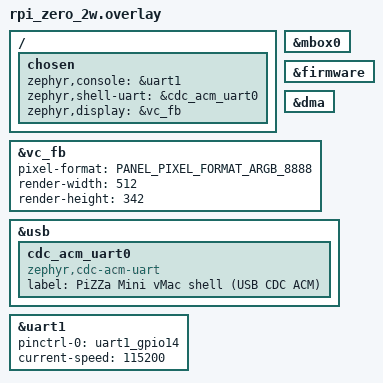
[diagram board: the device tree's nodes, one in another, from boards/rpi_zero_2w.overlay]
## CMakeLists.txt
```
# SPDX-License-Identifier: Apache-2.0
#
# PiZZa -- Mini vMac (Macintosh Plus) via the shared minimal SDL2 shim
# (apps/lib/sdl2shim). Third consumer after Doom + SDLPoP.
#
# Links the upstream Mini vMac 68K emulator core + its generated SDL2
# OS-glue (OSGLUSDL.c) against the shim. The tree at ~/github/minivmac is
# UNTOUCHED: src/ is pristine upstream, and the Mac-Plus/SDL2 variation is
# the generated cfg/ headers (setup_t -m Plus -api sd2). See the port memory.
#
# Mini vMac is GPL-2.0; this binary is GPL-2.0 by virtue of linking it. The
# shim + port glue are Apache-2.0, same model as the Doom + SDLPoP ports.

cmake_minimum_required(VERSION 3.20.0)

find_package(Zephyr REQUIRED HINTS $ENV{ZEPHYR_BASE})
project(pizza-minivmac C ASM)

# sample_usbd helper for the USB CDC ACM shell (rpi_zero_2w), same as the
# Doom / SDLPoP / wipeout ports.
if(CONFIG_USB_DEVICE_STACK_NEXT)
  include(${ZEPHYR_BASE}/samples/subsys/usb/common/common.cmake)
endif()

# ── Mini vMac tree (untouched upstream + generated cfg/) ─────────────
if(NOT DEFINED MINIVMAC_SRC_DIR)
  set(MINIVMAC_SRC_DIR "$ENV{HOME}/github/minivmac")
endif()
if(NOT EXISTS "${MINIVMAC_SRC_DIR}/src/OSGLUSDL.c")
  message(FATAL_ERROR
    "Mini vMac sources not found at ${MINIVMAC_SRC_DIR}. Clone "
    "https://github.com/minivmac/minivmac and keep it at ~/github/minivmac "
    "or pass -DMINIVMAC_SRC_DIR=<path>.")
endif()
if(NOT EXISTS "${MINIVMAC_SRC_DIR}/cfg/CNFUIOSG.h")
  message(FATAL_ERROR
    "Mini vMac Mac-Plus/SDL2 variation not generated in ${MINIVMAC_SRC_DIR}. Run:\n"
    "  cd ${MINIVMAC_SRC_DIR} && gcc -o setup_t setup/tool.c && \\\n"
    "  ./setup_t -e bgc -t larm -cpu a64 -m Plus -api sd2 -sound 1 > setup.sh && bash setup.sh")
endif()

# The generated Makefile's TU list for -m Plus -api sd2: the 68K core +
# device models + the SDL2 OS-glue. Untouched upstream.
set(MINIVMAC_SRC
  ${MINIVMAC_SRC_DIR}/src/OSGLUSDL.c
  ${MINIVMAC_SRC_DIR}/src/GLOBGLUE.c
  ${MINIVMAC_SRC_DIR}/src/M68KITAB.c
  ${MINIVMAC_SRC_DIR}/src/MINEM68K.c
  ${MINIVMAC_SRC_DIR}/src/VIAEMDEV.c
  ${MINIVMAC_SRC_DIR}/src/IWMEMDEV.c
  ${MINIVMAC_SRC_DIR}/src/SCCEMDEV.c
  ${MINIVMAC_SRC_DIR}/src/RTCEMDEV.c
  ${MINIVMAC_SRC_DIR}/src/ROMEMDEV.c
  ${MINIVMAC_SRC_DIR}/src/SCSIEMDV.c
  ${MINIVMAC_SRC_DIR}/src/SONYEMDV.c
  ${MINIVMAC_SRC_DIR}/src/SCRNEMDV.c
  ${MINIVMAC_SRC_DIR}/src/MOUSEMDV.c
  ${MINIVMAC_SRC_DIR}/src/KBRDEMDV.c
  ${MINIVMAC_SRC_DIR}/src/SNDEMDEV.c
  ${MINIVMAC_SRC_DIR}/src/PROGMAIN.c
)

# ── shim ─────────────────────────────────────────────────────────────
include(${CMAKE_CURRENT_SOURCE_DIR}/../lib/sdl2shim/sdl2shim.cmake)

set(MINIVMAC_SHIM_SRC
  src/shim_main.c
  src/minivmac_video.c
  src/minivmac_assets.c
  src/minivmac_pack.S
)

if(CONFIG_MINIVMAC_PRESENT_DISPLAY)
  list(APPEND MINIVMAC_SHIM_SRC src/minivmac_present_display.c)
elseif(CONFIG_MINIVMAC_PRESENT_SEMIHOST)
  list(APPEND MINIVMAC_SHIM_SRC src/minivmac_present_semihost.c)
else()
  list(APPEND MINIVMAC_SHIM_SRC src/minivmac_present_none.c)
endif()

# Audio backend (lib-owned choice): qemu uses "none" (Mac boots silent);
# rpi_zero_2w uses the HDMI/MAI backend later (Phase 7).
if(CONFIG_SDL2SHIM_AUDIO_HDMI)
  list(APPEND MINIVMAC_SHIM_SRC ${SDL2SHIM_AUDIO_HDMI_SOURCES})
else()
  list(APPEND MINIVMAC_SHIM_SRC ${SDL2SHIM_AUDIO_NONE})
endif()

# USB device bring-up + the `minivmac` shell = interactive input on
# hardware (key + mouse), wired at Phase 4/5.
if(CONFIG_USB_DEVICE_STACK_NEXT)
  list(APPEND MINIVMAC_SHIM_SRC ${SDL2SHIM_USB})
endif()

# The `minivmac` shell (key + mouse/click) = interactive input on hardware.
if(CONFIG_SHELL)
  list(APPEND MINIVMAC_SHIM_SRC src/minivmac_shell.c)
endif()

# Scripted synthetic input drives the Finder for the qemu sim gate.
if(CONFIG_MINIVMAC_SCRIPTED_INPUT)
  list(APPEND MINIVMAC_SHIM_SRC src/minivmac_scripted.c)
endif()

# Persistent disk backing on a mounted FATFS volume (SD card / RAM-FAT).
if(CONFIG_MINIVMAC_DISK_FS)
  list(APPEND MINIVMAC_SHIM_SRC src/minivmac_storage.c)
endif()

# BT HID input (keyboard + mouse) via apps/lib/btinput -- rpi_zero_2w only
# (boards/rpi_zero_2w.conf sets CONFIG_BTINPUT; qemu has no radio).
if(CONFIG_BTINPUT)
  include(${CMAKE_CURRENT_SOURCE_DIR}/../lib/btinput/btinput.cmake)
  # The BT patchram (.hcd) is a gitignored vendor blob (PROVENANCE.md).
  # Fail LOUDLY if missing: an empty-patchram image wedges the controller
  # at runtime (Download_Minidriver with nothing to launch).
  if(NOT CONFIG_AIROC_CUSTOM_FIRMWARE_HCD_BLOB)
    message(FATAL_ERROR
      "minivmac+BTINPUT: CONFIG_AIROC_CUSTOM_FIRMWARE_HCD_BLOB is unset")
  endif()
  set(_bt_blob "${CONFIG_AIROC_CUSTOM_FIRMWARE_HCD_BLOB}")
  if(NOT IS_ABSOLUTE "${_bt_blob}")
    set(_bt_blob "${CMAKE_CURRENT_SOURCE_DIR}/${_bt_blob}")
  endif()
  if(NOT EXISTS "${_bt_blob}")
    message(FATAL_ERROR
      "minivmac+BTINPUT: BT patchram not found:\n  ${_bt_blob}\n"
      "It is gitignored (vendor blob) -- fetch it per "
      "apps/lib/btinput/firmware/PROVENANCE.md before building.")
  endif()
  list(APPEND MINIVMAC_SHIM_SRC ${BTINPUT_SOURCES} src/minivmac_btinput.c)
endif()

# ── ROM bake (§5): raw .incbin into rodata ──────────────────────────
if(NOT DEFINED MINIVMAC_ROM)
  set(MINIVMAC_ROM "${MINIVMAC_SRC_DIR}/extras/roms/vMac.ROM")
endif()
if(NOT EXISTS "${MINIVMAC_ROM}")
  message(FATAL_ERROR "Mac Plus ROM not found: ${MINIVMAC_ROM}. Pass -DMINIVMAC_ROM=<path/to/vMac.ROM>.")
endif()
set(MINIVMAC_ROM_BIN ${CMAKE_BINARY_DIR}/minivmac_rom.bin)
add_custom_command(
  OUTPUT ${MINIVMAC_ROM_BIN}
  COMMAND ${CMAKE_COMMAND} -E copy ${MINIVMAC_ROM} ${MINIVMAC_ROM_BIN}
  DEPENDS ${MINIVMAC_ROM}
  COMMENT "Baking Mac Plus ROM ${MINIVMAC_ROM} into rodata"
)
add_custom_target(minivmac_rom_bake DEPENDS ${MINIVMAC_ROM_BIN})
add_dependencies(app minivmac_rom_bake)

# ── Boot disk bake (Phase 3): a bootable System 6.0.8 floppy into rodata,
# served through a writable RAM overlay (minivmac_assets.c). Default is the
# Startup floppy shipped in the pinned tree; the 100 MB HD image cannot be
# RAM-backed (SD/FAT persistence is a later phase).
if(NOT DEFINED MINIVMAC_DISK)
  set(MINIVMAC_DISK "${MINIVMAC_SRC_DIR}/extras/disks/608/Z-690-5830-B (Startup).img")
endif()
if(NOT EXISTS "${MINIVMAC_DISK}")
  message(FATAL_ERROR "Boot disk not found: ${MINIVMAC_DISK}. Pass -DMINIVMAC_DISK=<path/to/bootable.dsk>.")
endif()
set(MINIVMAC_DISK_BIN ${CMAKE_BINARY_DIR}/minivmac_disk.dsk)
add_custom_command(
  OUTPUT ${MINIVMAC_DISK_BIN}
  COMMAND ${CMAKE_COMMAND} -E copy "${MINIVMAC_DISK}" ${MINIVMAC_DISK_BIN}
  DEPENDS "${MINIVMAC_DISK}"
  COMMENT "Baking boot disk into rodata"
  VERBATIM
)
add_custom_target(minivmac_disk_bake DEPENDS ${MINIVMAC_DISK_BIN})
add_dependencies(app minivmac_disk_bake)

set_source_files_properties(src/minivmac_pack.S PROPERTIES
  OBJECT_DEPENDS "${MINIVMAC_ROM_BIN};${MINIVMAC_DISK_BIN}"
  COMPILE_OPTIONS "-I${CMAKE_BINARY_DIR};-Wa,-I${CMAKE_BINARY_DIR}"
)

# ── target ───────────────────────────────────────────────────────────
target_sources(app PRIVATE
  ${MINIVMAC_SRC}
  ${MINIVMAC_SHIM_SRC}
  ${SDL2SHIM_CORE_SOURCES}
)

# include order: shim SDL2 headers first so <SDL2/SDL.h> (pulled by
# cfg/CNFUIOSG.h) resolves to the shim, then the Mini vMac variation cfg/
# and the pristine upstream src/.
target_include_directories(app PRIVATE
  ${SDL2SHIM_INCLUDE_DIRS}
  ${CMAKE_CURRENT_SOURCE_DIR}/src
  ${MINIVMAC_SRC_DIR}/cfg
  ${MINIVMAC_SRC_DIR}/src
)
if(CONFIG_BTINPUT)
  target_include_directories(app PRIVATE ${BTINPUT_INCLUDE_DIRS})
endif()

# Mini vMac TUs are pristine upstream ANSI C; silence the pedantic warnings
# its own build (and picolibc's stricter headers) would otherwise raise.
set_source_files_properties(${MINIVMAC_SRC} PROPERTIES COMPILE_OPTIONS
  "-Wno-unused-variable;-Wno-unused-but-set-variable;-Wno-unused-function;-Wno-missing-braces;-Wno-implicit-fallthrough;-Wno-format;-Wno-sign-compare;-D_DEFAULT_SOURCE"
)
```

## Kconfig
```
# SPDX-License-Identifier: Apache-2.0
#
# PiZZa Mini vMac port -- app options. Backend choices are the seams the
# app's CMakeLists uses to pick the present TU.

# SAMPLE_USBD_* options for sample_usbd_init.c on boards with the USB
# device stack (rpi_zero_2w), same as the Doom / SDLPoP ports.
source "samples/subsys/usb/common/Kconfig.sample_usbd"

rsource "../lib/sdl2shim/Kconfig"
rsource "../lib/btinput/Kconfig"

menu "PiZZa Mini vMac port"

choice MINIVMAC_PRESENT_BACKEND
	prompt "Frame present backend"
	default MINIVMAC_PRESENT_DISPLAY if DISPLAY
	default MINIVMAC_PRESENT_NONE

config MINIVMAC_PRESENT_DISPLAY
	bool "Zephyr display API (bcm2835_fb + HVS scaling on hardware)"
	depends on DISPLAY

config MINIVMAC_PRESENT_NONE
	bool "Drop frames (link/sim bring-up)"

config MINIVMAC_PRESENT_SEMIHOST
	bool "Semihosting PPM capture (qemu sim gates)"
	depends on SEMIHOST

endchoice

config MINIVMAC_CAPTURE_EVERY
	int "Capture every Nth presented frame (0 = first frame only)"
	depends on MINIVMAC_PRESENT_SEMIHOST
	default 0

config MINIVMAC_SCRIPTED_INPUT
	bool "Drive Mini vMac from a scripted synthetic input source"
	default n

config MINIVMAC_DISK_FS
	bool "Back the boot disk with a file on a mounted FATFS (SD card)"
	default n
	select DISK_ACCESS
	select FILE_SYSTEM
	select FAT_FILESYSTEM_ELM
	help
	  Store the .dsk as a real file (minivmac.dsk) on a FATFS volume -- the
	  microSD card on rpi_zero_2w -- instead of a non-persistent RAM overlay,
	  so guest OS writes survive a reboot. Seeded from the embedded floppy on
	  first run. Falls back to the RAM overlay if the mount fails, so it is
	  safe to leave on where no card is present.

config MINIVMAC_FS_MOUNT
	string "FATFS mount point / ELM volume holding the disk file"
	depends on MINIVMAC_DISK_FS
	default "/SD:"
	help
	  The disk-access volume to mount, e.g. "/SD:" for the SD card
	  (zephyr,sdmmc-disk disk-name "SD") or "/RAM:" for a RAM-backed FAT disk
	  on qemu. minivmac.dsk is stored at <mount>/minivmac.dsk.

config MINIVMAC_DISK_SELFTEST
	bool "Verify the disk round-trip against the embedded seed at boot"
	depends on MINIVMAC_DISK_FS
	default n
	help
	  Debug aid: after mounting + seeding, read the whole disk back from the
	  volume and diff it against the embedded floppy, logging OK or the
	  corrupt sectors on the console. Confirms whether the storage driver's
	  data path round-trips faithfully.

endmenu

source "Kconfig.zephyr"
```

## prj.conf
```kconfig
# SPDX-License-Identifier: Apache-2.0
#
# Common config for the PiZZa Mini vMac port. Per-board overrides
# (display, USB, audio) live in boards/<board>.conf.

CONFIG_PRINTK=y
CONFIG_BOOT_BANNER=y
CONFIG_LOG_PRINTK=n

# picolibc errno needs TLS -- the same hard-won stanza as the Doom /
# wipeout / SDLPoP ports; without it the first failing stdio call
# scribbles through a wild TPIDRRO_EL0 offset.
CONFIG_TOOLCHAIN_CROSS_COMPILE_SUPPORTS_THREAD_LOCAL_STORAGE=y
CONFIG_THREAD_LOCAL_STORAGE=y

# Mac Plus = 4 MiB emulated RAM + the 128 KiB ROM + the 512x342 ARGB
# streaming texture + Mini vMac's scaling/CLUT buffers. 32 MiB covers it
# with headroom on both the 512 MiB board and qemu.
CONFIG_COMMON_LIBC_MALLOC_ARENA_SIZE=33554432

# The emulator runs on the Zephyr main thread; PROGMAIN + the OS-glue
# call chains run deep.
CONFIG_MAIN_STACK_SIZE=65536

CONFIG_FPU=y
CONFIG_STACK_SENTINEL=y
CONFIG_ASSERT=y
```

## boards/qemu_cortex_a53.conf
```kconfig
# SPDX-License-Identifier: Apache-2.0
#
# qemu_cortex_a53 -- SIM target. Phase 1: semihost PPM capture to visually
# confirm the Mac boot screen (happy Mac -> disk-request icon) renders at
# 512x342 with correct black-on-white polarity. qemu gets the semihosting
# flags from cmake/emu/qemu.cmake when CONFIG_SEMIHOST.

# Run the emulated CPU at wall speed; -icount stretches the 68K interpreter.
CONFIG_QEMU_ICOUNT=n

CONFIG_SEMIHOST=y
CONFIG_MINIVMAC_PRESENT_SEMIHOST=y
CONFIG_MINIVMAC_CAPTURE_EVERY=60

# Drive the booted Finder with a scripted mouse + keyboard timeline.
CONFIG_MINIVMAC_SCRIPTED_INPUT=y

# Phase 6 sim gate: exercise the FS-backed disk path (mount + seed + fs
# read/write + boot-to-Finder) on a RAM-backed FAT volume standing in for the
# SD card. Auto-format the blank ramdisk -- qemu ONLY; never enabled on HW.
CONFIG_MINIVMAC_DISK_FS=y
CONFIG_MINIVMAC_FS_MOUNT="/RAM:"
CONFIG_DISK_DRIVER_RAM=y
CONFIG_FS_FATFS_MOUNT_MKFS=y

CONFIG_LOG=y
CONFIG_LOG_MODE_MINIMAL=y
CONFIG_SDL2SHIM_LOG_LEVEL_DBG=y
```

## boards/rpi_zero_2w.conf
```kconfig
# SPDX-License-Identifier: Apache-2.0
#
# Raspberry Pi Zero 2 W (BCM2710, Cortex-A53, AArch64) -- Mini vMac.
# Single-core (the 68K emulator is single-threaded; no SMP). Console + logs
# on the mini-UART, interactive `minivmac` shell (keyboard + mouse) on USB
# CDC ACM, HDMI via the VC firmware framebuffer with HVS 512x342 scaling.
# Audio is deferred (Phase 7): the Mac boots silent on the "none" backend.

CONFIG_BOOT_DELAY=200

# VC mailbox + firmware (framebuffer alloc chain).
CONFIG_RASPBERRYPI_FIRMWARE=y

# HDMI display via VC firmware FB, ARGB_8888. The shim paints the Mac's
# native 512x342 frame into the virtual FB; the HVS scales to the monitor.
CONFIG_DISPLAY=y
CONFIG_BCM2835_FB=y

# BCM2835 DMA -- the FB driver claims a channel for the backbuffer blit.
CONFIG_DMA=y
CONFIG_DMA_BCM2835=y

# Phase 6: persistent boot disk on the microSD card. The BCM SDHost driver +
# zephyr,sdmmc-disk "SD" (both from the board DTS) carry a FATFS volume; the
# disk becomes /SD:/minivmac.dsk and guest writes survive reboot.
CONFIG_MINIVMAC_DISK_FS=y

# The disk round-trip selftest is an opt-in debug aid
# (CONFIG_MINIVMAC_DISK_SELFTEST=y); it force-reseeds the disk each boot, so
# leave it off here so guest writes persist across reboots.

# SAFETY: never auto-format the card. FS_FATFS_MOUNT_MKFS defaults y, which
# would reformat (wipe) the SD on any mount failure; force it off so a failed
# mount falls back to the RAM overlay instead of destroying the user's card.
CONFIG_FS_FATFS_MOUNT_MKFS=n

# USB CDC ACM shell, same shape as the Doom / wipeout ports. The `minivmac`
# command set (inject keyboard + mouse events) registers here.
CONFIG_USB_DEVICE_STACK_NEXT=y
CONFIG_UDC_DWC2=y
CONFIG_UDC_DWC2_DMA=n
CONFIG_SERIAL=y
CONFIG_USBD_CDC_ACM_CLASS=y
CONFIG_CDC_ACM_SERIAL_INITIALIZE_AT_BOOT=n
CONFIG_SAMPLE_USBD_PRODUCT="PiZZa Mini vMac -- rpi_zero_2w"
CONFIG_SAMPLE_USBD_MANUFACTURER="jetpax/PiZZa"
CONFIG_SAMPLE_USBD_PID=0x6800
CONFIG_USBD_THREAD_STACK_SIZE=4096
CONFIG_UDC_DWC2_STACK_SIZE=4096

CONFIG_SHELL=y
CONFIG_SHELL_BACKEND_SERIAL=y
CONFIG_KERNEL_SHELL=y
CONFIG_SHELL_STACK_SIZE=8192
CONFIG_SHELL_VT100_COMMANDS=y
CONFIG_SHELL_HISTORY=y
CONFIG_SHELL_TAB=y
CONFIG_SHELL_LOG_BACKEND=n

# Logging on the board console (mini-UART), off the shell prompt.
CONFIG_LOG=y
CONFIG_LOG_BUFFER_SIZE=16384
CONFIG_LOG_BACKEND_UART=y
CONFIG_LOG_MODE_DEFERRED=y
CONFIG_USBD_CDC_ACM_LOG_LEVEL_WRN=y
CONFIG_USBD_LOG_LEVEL_INF=y
CONFIG_UDC_DRIVER_LOG_LEVEL_WRN=y

# ── Bluetooth HID input (M4.5: 8BitDo pad keys + BT mouse into the Mac) ──
# Stack, host profile and connection policy all live in apps/lib/btinput;
# config mirrors the HW-proven bring-up harness settings. No
# keymap remap here: BT keyboard usages ARE SDL scancodes, so pad keys
# type letters into the Finder; the mouse drives the Mac cursor via the
# seam's absolute position (bounds 512x342 in minivmac_btinput.c).
CONFIG_BTINPUT=y
CONFIG_BTINPUT_HOGP=y
CONFIG_BTINPUT_SEAM_SDL=y
CONFIG_BTINPUT_MANAGER=y

CONFIG_BT=y
CONFIG_BT_CLASSIC=y
CONFIG_BT_DEVICE_NAME="PiZZa"
CONFIG_BT_MAX_PAIRED=8
CONFIG_BT_MAX_CONN=3
# The 8BitDo's fw is legacy-only SMP; Just Works is the accepted trust model.
CONFIG_BT_SMP_SC_PAIR_ONLY=n
# The 4.2 controller has 1M PHY only; skip the doomed LE Set PHY attempt.
CONFIG_BT_AUTO_PHY_UPDATE=n

# Infineon AIROC patchram: this unit is the Synaptics 43436S module
# (BT ROM = 43430A1). Blob is gitignored; PROVENANCE.md has the fetch.
CONFIG_BT_AIROC=y
CONFIG_BT_AIROC_CUSTOM=y
CONFIG_AIROC_CUSTOM_FIRMWARE_HCD_BLOB="../lib/btinput/firmware/SYN43430A1.hcd"

# Bond persistence: settings FILE backend on the SD FAT. The app's disk-fs
# mounts /SD: first (minivmac_btinput.c ordering); the manager tolerates
# the already-mounted volume. MKFS stays off (see above).
CONFIG_BT_SETTINGS=y
CONFIG_SETTINGS=y
CONFIG_SETTINGS_FILE=y
CONFIG_SETTINGS_FILE_PATH="/SD:/bt/settings"
CONFIG_DISK_ACCESS=y
CONFIG_DISK_DRIVERS=y
CONFIG_SDMMC_SUBSYS=y
CONFIG_FILE_SYSTEM=y
CONFIG_FAT_FILESYSTEM_ELM=y
CONFIG_FS_FATFS_LFN=y
CONFIG_FILE_SYSTEM_MKFS=n

# aarch64: BT stack defaults are Cortex-M sized; P-256 on the long WQ
# needs 8K frames (instruction-abort class otherwise).
CONFIG_BT_LONG_WQ_STACK_SIZE=8192
CONFIG_BT_RX_STACK_SIZE=8192
CONFIG_BT_HCI_TX_STACK_SIZE_WITH_PROMPT=y
CONFIG_BT_HCI_TX_STACK_SIZE=4096
CONFIG_SYSTEM_WORKQUEUE_STACK_SIZE=8192
CONFIG_THREAD_NAME=y

# ELM FatFs is NOT thread-safe by default, and this image has two FatFs
# users on different threads: the emulator reading minivmac.dsk (main)
# and the BT bond store (btinput manager thread + system workqueue).
# Without the per-volume mutex the colliding calls share the FATFS
# sector window -- settings_load saw spurious FR_NO_FILE and bond saves
# were silently lost (HW 2026-07-08: bonds never persisted a reboot).
# REENTRANT requires the LFN buffer off BSS (stack mode).
CONFIG_FS_FATFS_REENTRANT=y
CONFIG_FS_FATFS_LFN_MODE_STACK=y

# A re-pairing peer whose new identity info (IRK) resolves an EXISTING bond
# entry is otherwise REFUSED by smp.c ("the old bond must be unpaired
# first") -- observed with the MX Master after bond litter accumulated
# under its rotating addresses (HW 2026-07-08): every reconnect became a
# pairing attempt that conflicted with a stale bond, mouse unreachable.
# With this, the stack unpairs the conflicting stale bond (trust-checked)
# and the pairing completes -- self-healing, no card surgery.
CONFIG_BT_ID_UNPAIR_MATCHING_BONDS=y
# ...and the trust check's final branch refuses JW-over-JW overwrites
# without this (smp.c update_keys_check: "old bond has more trust").
# JW has no MITM protection anyway -- the WO-accepted trust model.
CONFIG_BT_SMP_ALLOW_UNAUTH_OVERWRITE=y
```

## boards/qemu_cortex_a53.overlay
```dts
/*
 * SPDX-License-Identifier: Apache-2.0
 *
 * PiZZa Mini vMac overlay for qemu_cortex_a53 (sim gate).
 *
 * A RAM-backed FAT disk ("RAM") so the persistent-disk code path
 * (CONFIG_MINIVMAC_DISK_FS: mount + seed + fs read/write + boot-to-Finder) is
 * exercised in sim, standing in for the SD card the hardware uses. ~4.6 MB
 * holds the 1.44 MB seed floppy plus FAT overhead.
 */

/ {
	ramdisk0 {
		compatible = "zephyr,ram-disk";
		disk-name = "RAM";
		sector-size = <512>;
		sector-count = <9000>;
	};
};
```

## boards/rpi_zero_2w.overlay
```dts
/*
 * SPDX-License-Identifier: Apache-2.0
 *
 * PiZZa Mini vMac overlay for rpi_zero_2w.
 *
 *   - &mbox0 + &firmware: VC mailbox + property tags (FB alloc).
 *   - &vc_fb: HDMI framebuffer at the monitor's EDID-negotiated scanout
 *     mode; the shim paints the Mac's native 512x342 frame into the virtual
 *     FB and the VideoCore HVS scales it to the cable on the fly -- the same
 *     proven trick as the Doom / wipeout / SDLPoP ports. 512 * 4 = 2048
 *     bytes/row = 64-byte aligned, so the FB driver's contiguous-DMA fast
 *     path engages.
 *   - &dma: BCM2835 DMA (backbuffer->fb blit).
 *   - &usb + cdc_acm child: USB CDC ACM `minivmac` shell endpoint.
 *   - mini-UART (uart1) console + LOG target, PiZZa convention.
 */

#include <zephyr/dt-bindings/display/panel.h>

&mbox0 {
	status = "okay";
};

&firmware {
	status = "okay";
};

&dma {
	status = "okay";
};

&vc_fb {
	pixel-format = <PANEL_PIXEL_FORMAT_ARGB_8888>;
	render-width = <512>;
	render-height = <342>;
	status = "okay";
};

&usb {
	status = "okay";

	cdc_acm_uart0: cdc_acm_uart0 {
		compatible = "zephyr,cdc-acm-uart";
		label = "PiZZa Mini vMac shell (USB CDC ACM)";
	};
};

/ {
	chosen {
		zephyr,console = &uart1;
		zephyr,shell-uart = &cdc_acm_uart0;
		zephyr,display = &vc_fb;
	};
};

&uart1 {
	pinctrl-names = "default";
	pinctrl-0 = <&uart1_gpio14>;
	status = "okay";
	current-speed = <115200>;
};
```

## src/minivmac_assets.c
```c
/*
 * SPDX-License-Identifier: Apache-2.0
 *
 * PiZZa Mini vMac -- embedded asset store: ROM (read-only) + boot disk
 * (writable).
 *
 * The ROM and a seed floppy are linked into .rodata (minivmac_pack.S,
 * .incbin); this file serves them through a POSIX fd layer, so OSGLUSDL.c's
 * fopen/fread/fwrite/fseek (funnelled by picolibc tinystdio through
 * open/read/write/lseek/close/fstat) resolve here with no filesystem on the
 * boot path and the Mini vMac tree untouched.
 *
 *  - ROM ("vMac.ROM"): read-only rodata. LoadMacRom() lands here.
 *  - Boot disk ("boot.dsk"): two backings, chosen at open time.
 *      * CONFIG_MINIVMAC_DISK_FS: a real file on a mounted FATFS volume (the
 *        SD card), via minivmac_storage.c -- writes PERSIST across reboot.
 *      * otherwise / on mount failure: a heap RAM overlay copied from the
 *        embedded floppy -- writable but non-persistent.
 */

#include <zephyr/kernel.h>
#include <errno.h>
#include <fcntl.h>
#include <stdint.h>
#include <stdlib.h>
#include <string.h>
#include <strings.h>
#include <sys/stat.h>
#include <sys/types.h>
#include <unistd.h>

#ifdef CONFIG_MINIVMAC_DISK_FS
#include "minivmac_storage.h"
#endif

extern const uint8_t minivmac_rom_start[];
extern const uint8_t minivmac_rom_end[];
extern const uint8_t minivmac_disk_start[];
extern const uint8_t minivmac_disk_end[];

#define MINIVMAC_FD_BASE 3
#define MINIVMAC_FD_MAX  4

enum fd_kind {
	FD_FREE = 0,
	FD_ROM,
	FD_DISK_RAM,
	FD_DISK_SD,
};

static struct {
	size_t pos;
	enum fd_kind kind;
} fds[MINIVMAC_FD_MAX];

/* RAM overlay for the boot disk, materialized on first open (fallback path). */
static uint8_t *disk_ram;
static size_t disk_len;

static size_t rom_size(void)
{
	return (size_t)(minivmac_rom_end - minivmac_rom_start);
}

static size_t disk_image_size(void)
{
	return (size_t)(minivmac_disk_end - minivmac_disk_start);
}

static bool ends_with(const char *path, const char *suffix)
{
	if (path == NULL) {
		return false;
	}

	size_t n = strlen(path);
	size_t m = strlen(suffix);

	return n >= m && strcasecmp(path + n - m, suffix) == 0;
}

static bool is_rom(const char *path)
{
	return ends_with(path, "vMac.ROM");
}

static bool is_disk(const char *path)
{
	return ends_with(path, "boot.dsk");
}

static bool disk_ram_ready(void)
{
	if (disk_ram == NULL) {
		disk_len = disk_image_size();
		disk_ram = malloc(disk_len);
		if (disk_ram == NULL) {
			return false;
		}
		memcpy(disk_ram, minivmac_disk_start, disk_len);
	}
	return true;
}

int open(const char *path, int flags, ...)
{
	enum fd_kind kind;

	if (is_disk(path)) {
#ifdef CONFIG_MINIVMAC_DISK_FS
		if (minivmac_storage_disk_init() == 0) {
			kind = FD_DISK_SD;
		} else
#endif
		if (disk_image_size() == 0 || !disk_ram_ready()) {
			errno = ENOENT;
			return -1;
		} else {
			kind = FD_DISK_RAM;
		}
	} else if ((flags & O_ACCMODE) != O_RDONLY) {
		errno = EROFS;
		return -1;
	} else if (is_rom(path) && rom_size() > 0) {
		kind = FD_ROM;
	} else {
		errno = ENOENT;
		return -1;
	}

	for (int i = 0; i < MINIVMAC_FD_MAX; i++) {
		if (fds[i].kind == FD_FREE) {
			fds[i].pos = 0;
			fds[i].kind = kind;
			return MINIVMAC_FD_BASE + i;
		}
	}
	errno = EMFILE;
	return -1;
}

static int fd_slot(int fd)
{
	int i = fd - MINIVMAC_FD_BASE;

	if (i < 0 || i >= MINIVMAC_FD_MAX || fds[i].kind == FD_FREE) {
		return -1;
	}
	return i;
}

static size_t slot_size(int i)
{
	switch (fds[i].kind) {
#ifdef CONFIG_MINIVMAC_DISK_FS
	case FD_DISK_SD:
		return minivmac_storage_disk_size();
#endif
	case FD_DISK_RAM:
		return disk_len;
	default:
		return rom_size();
	}
}

int close(int fd)
{
	int i = fd_slot(fd);

	if (i < 0) {
		errno = EBADF;
		return -1;
	}
	fds[i].kind = FD_FREE;
	return 0;
}

ssize_t read(int fd, void *buf, size_t count)
{
	int i = fd_slot(fd);

	if (i < 0) {
		errno = EBADF;
		return -1;
	}

#ifdef CONFIG_MINIVMAC_DISK_FS
	if (fds[i].kind == FD_DISK_SD) {
		ssize_t n = minivmac_storage_disk_read(buf, count, fds[i].pos);

		if (n < 0) {
			errno = EIO;
			return -1;
		}
		fds[i].pos += (size_t)n;
		return n;
	}
#endif

	const uint8_t *src = (fds[i].kind == FD_DISK_RAM) ? disk_ram : minivmac_rom_start;
	size_t avail = slot_size(i) - fds[i].pos;
	size_t n = MIN(count, avail);

	memcpy(buf, src + fds[i].pos, n);
	fds[i].pos += n;
	return (ssize_t)n;
}

ssize_t write(int fd, const void *buf, size_t count)
{
	int i = fd_slot(fd);

	if (i < 0) {
		errno = EBADF;
		return -1;
	}

#ifdef CONFIG_MINIVMAC_DISK_FS
	if (fds[i].kind == FD_DISK_SD) {
		ssize_t n = minivmac_storage_disk_write(buf, count, fds[i].pos);

		if (n < 0) {
			errno = EIO;
			return -1;
		}
		fds[i].pos += (size_t)n;
		return n;
	}
#endif

	if (fds[i].kind != FD_DISK_RAM) {
		errno = EROFS;
		return -1;
	}

	/* Disk images are fixed size; writes stay within existing sectors. */
	size_t space = disk_len - fds[i].pos;
	size_t n = MIN(count, space);

	memcpy(disk_ram + fds[i].pos, buf, n);
	fds[i].pos += n;
	if (n < count) {
		errno = ENOSPC;
	}
	return (ssize_t)n;
}

off_t lseek(int fd, off_t offset, int whence)
{
	int i = fd_slot(fd);

	if (i < 0) {
		errno = EBADF;
		return (off_t)-1;
	}

	off_t fsize = (off_t)slot_size(i);
	off_t base;

	switch (whence) {
	case SEEK_SET:
		base = 0;
		break;
	case SEEK_CUR:
		base = (off_t)fds[i].pos;
		break;
	case SEEK_END:
		base = fsize;
		break;
	default:
		errno = EINVAL;
		return (off_t)-1;
	}

	off_t target = base + offset;

	if (target < 0 || target > fsize) {
		errno = EINVAL;
		return (off_t)-1;
	}
	fds[i].pos = (size_t)target;
	return target;
}

int fstat(int fd, struct stat *st)
{
	int i = fd_slot(fd);

	if (i < 0) {
		errno = EBADF;
		return -1;
	}
	memset(st, 0, sizeof(*st));
	st->st_size = (off_t)slot_size(i);
	st->st_mode = S_IFREG | ((fds[i].kind == FD_ROM) ? 0444 : 0644);
	return 0;
}

int stat(const char *path, struct stat *st)
{
	off_t size;
	mode_t mode;

	if (is_disk(path) && disk_image_size() > 0) {
		size = (off_t)disk_image_size();
		mode = S_IFREG | 0644;
	} else if (is_rom(path) && rom_size() > 0) {
		size = (off_t)rom_size();
		mode = S_IFREG | 0444;
	} else {
		errno = ENOENT;
		return -1;
	}
	memset(st, 0, sizeof(*st));
	st->st_size = size;
	st->st_mode = mode;
	return 0;
}
```

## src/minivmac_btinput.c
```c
/*
 * SPDX-License-Identifier: Apache-2.0
 *
 * PiZZa Mini vMac -- Bluetooth HID input (CONFIG_BTINPUT).
 *
 * Everything lives in apps/lib/btinput (manager = bring-up + connection
 * policy on its own thread; SDL seam = events into the sdl2shim queue that
 * OSGLUSDL.c already drains). Consumer policy here is minimal:
 *
 *  - NO keymap: a BT keyboard's usages pass through 1:1 (they ARE SDL
 *    scancodes), so the 8BitDo's stock K-mode letters TYPE letters into the
 *    Mac -- which is exactly the keyboard test. Mini vMac's SDLScan2MacKeyCode
 *    handles the rest.
 *  - Bounds = the Mac Plus screen (512x342): Mini vMac polls the absolute
 *    position via SDL_GetMouseState every tick, so the seam's integrated
 *    position maps 1:1 onto the Mac cursor.
 *  - Mount ordering: the manager mounts /SD: for the settings bond store,
 *    but this app backs its BOOT DISK with /SD:/minivmac.dsk and its own
 *    fs_mount falls back to a non-persistent RAM overlay on ANY error --
 *    including the -EBUSY it would get if the manager's thread won the
 *    mount race. Init the app's disk first (idempotent); the manager then
 *    takes the already-mounted path.
 */

#include <zephyr/kernel.h>

#include "btinput.h"
#include "minivmac_storage.h"

void minivmac_btinput_start(void)
{
#ifdef CONFIG_MINIVMAC_DISK_FS
	minivmac_storage_disk_init();
#endif

	btinput_seam_sdl_set_bounds(512, 342);
	btinput_seam_sdl_attach();
	btinput_manager_start();
}
```

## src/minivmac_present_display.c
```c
/*
 * SPDX-License-Identifier: Apache-2.0
 *
 * PiZZa Mini vMac -- display present backend (CONFIG_MINIVMAC_PRESENT_DISPLAY).
 *
 * Pushes the Mac's 512x342 ARGB8888 frame at the Zephyr display API. On
 * rpi_zero_2w that is bcm2835_fb with a 512x342 virtual framebuffer (512 * 4
 * = 2048 B/row, 64-byte aligned so the driver's contiguous-DMA fast path
 * engages); the VideoCore HVS scales 512x342 to the monitor's native mode --
 * the same proven path as the Doom / wipeout / SDLPoP ports.
 *
 * Mini vMac's OSGLU already writes 0xFFRRGGBB (its CLUT maps 1-bit pixels
 * with an opaque alpha), but the scanout wants alpha forced opaque anyway, so
 * the per-pixel copy asserts it.
 */

#include <zephyr/kernel.h>
#include <zephyr/device.h>
#include <zephyr/drivers/display.h>
#include <zephyr/logging/log.h>

#include "sdl2shim.h"

LOG_MODULE_REGISTER(minivmac_present, CONFIG_SDL2SHIM_LOG_LEVEL);

#define MINIVMAC_W 512
#define MINIVMAC_H 342

static const struct device *display_dev;
static uint32_t backbuf[MINIVMAC_W * MINIVMAC_H];
static bool ready;

int s2s_present_init(int width, int height)
{
	if (width != MINIVMAC_W || height != MINIVMAC_H) {
		LOG_ERR("present: %dx%d requested, backend is fixed %dx%d",
			width, height, MINIVMAC_W, MINIVMAC_H);
		return -EINVAL;
	}

	display_dev = DEVICE_DT_GET(DT_CHOSEN(zephyr_display));
	if (!device_is_ready(display_dev)) {
		LOG_ERR("present: display device not ready -- HDMI not connected?");
		return -ENODEV;
	}

	struct display_capabilities caps;

	display_get_capabilities(display_dev, &caps);
	LOG_INF("present: display %ux%u (HVS virt) fmt=0x%x",
		caps.x_resolution, caps.y_resolution,
		(unsigned int)caps.current_pixel_format);

	if (caps.x_resolution != MINIVMAC_W || caps.y_resolution != MINIVMAC_H) {
		LOG_WRN("present: display reports %ux%u, expected %ux%u "
			"(check render-width/render-height in overlay)",
			caps.x_resolution, caps.y_resolution, MINIVMAC_W, MINIVMAC_H);
	}

	ready = true;
	return 0;
}

void s2s_present_frame(const void *argb_pixels, int pitch)
{
	if (!ready) {
		return;
	}

	const uint8_t *src_row = argb_pixels;
	uint32_t *dst = backbuf;

	for (int y = 0; y < MINIVMAC_H; y++) {
		const uint32_t *px = (const uint32_t *)src_row;

		for (int x = 0; x < MINIVMAC_W; x++) {
			*dst++ = 0xFF000000u | (px[x] & 0x00FFFFFFu);
		}
		src_row += pitch;
	}

	struct display_buffer_descriptor desc = {
		.buf_size = sizeof(backbuf),
		.width = MINIVMAC_W,
		.height = MINIVMAC_H,
		.pitch = MINIVMAC_W,
		.frame_incomplete = false,
	};

	int rc = display_write(display_dev, 0, 0, &desc, backbuf);

	if (rc != 0) {
		LOG_ERR("present: display_write rc=%d", rc);
	}
}
```

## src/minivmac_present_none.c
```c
/*
 * SPDX-License-Identifier: Apache-2.0
 *
 * PiZZa Mini vMac -- "none" present backend (CONFIG_MINIVMAC_PRESENT_NONE).
 * Frames are dropped; a periodic counter confirms the emulator is
 * presenting. Link/sim bring-up before the capture or display backend.
 */

#include <zephyr/kernel.h>
#include <zephyr/logging/log.h>

#include "sdl2shim.h"

LOG_MODULE_REGISTER(minivmac_present, CONFIG_SDL2SHIM_LOG_LEVEL);

static uint32_t frames;

int s2s_present_init(int width, int height)
{
	LOG_INF("present: none backend (%dx%d frames dropped)", width, height);
	return 0;
}

void s2s_present_frame(const void *argb_pixels, int pitch)
{
	ARG_UNUSED(argb_pixels);
	ARG_UNUSED(pitch);

	frames++;
	if ((frames % 64) == 0) {
		LOG_INF("present: %u frames", frames);
	}
}
```

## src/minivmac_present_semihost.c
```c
/*
 * SPDX-License-Identifier: Apache-2.0
 *
 * PiZZa Mini vMac -- semihosting capture present backend
 * (CONFIG_MINIVMAC_PRESENT_SEMIHOST, qemu sim gates).
 *
 * Frames land on the host filesystem as binary PPM (P6) files. The Mac
 * screen arrives as 512x342 ARGB8888 (0xAARRGGBB per pixel) from the
 * OSGLU's streaming texture; PPM wants R,G,B bytes, so each pixel is
 * unpacked on the way out (alpha dropped).
 *
 * Frame 1 is always written; with CONFIG_MINIVMAC_CAPTURE_EVERY=N > 0
 * every Nth frame is written too, so the boot progression (happy Mac ->
 * disk-request icon) is captured across several files.
 */

#include <zephyr/kernel.h>
#include <zephyr/arch/common/semihost.h>
#include <zephyr/logging/log.h>
#include <stdio.h>

#include "sdl2shim.h"

LOG_MODULE_REGISTER(minivmac_present, CONFIG_SDL2SHIM_LOG_LEVEL);

static int fb_w;
static int fb_h;
static uint32_t frames;

int s2s_present_init(int width, int height)
{
	fb_w = width;
	fb_h = height;
	LOG_INF("present: semihost capture backend (%dx%d)", width, height);
	return 0;
}

void s2s_present_frame(const void *argb_pixels, int pitch)
{
	frames++;

	bool capture = (frames == 1);

	if (CONFIG_MINIVMAC_CAPTURE_EVERY > 0 &&
	    (frames % CONFIG_MINIVMAC_CAPTURE_EVERY) == 0) {
		capture = true;
	}
	if (!capture) {
		return;
	}

	char name[48];
	char header[32];

	snprintf(name, sizeof(name), "minivmac_frame_%06u.ppm", frames);

	long fd = semihost_open(name, SEMIHOST_OPEN_WB);

	if (fd < 0) {
		LOG_ERR("present: semihost_open(%s) = %ld", name, fd);
		return;
	}

	int hlen = snprintf(header, sizeof(header), "P6\n%d %d\n255\n", fb_w, fb_h);

	semihost_write(fd, header, hlen);

	/* Unpack ARGB -> RGB one row at a time: 342 semihost writes/frame, not
	 * 175104. Row buffer sized for the wired 512-wide Mac Plus screen.
	 */
	static uint8_t rowbuf[512 * 3];
	const uint8_t *row = argb_pixels;

	for (int y = 0; y < fb_h; y++) {
		const uint32_t *px = (const uint32_t *)row;
		uint8_t *o = rowbuf;

		for (int x = 0; x < fb_w; x++) {
			uint32_t p = px[x];

			*o++ = (uint8_t)(p >> 16);  /* R */
			*o++ = (uint8_t)(p >> 8);   /* G */
			*o++ = (uint8_t)(p);        /* B */
		}
		semihost_write(fd, rowbuf, (long)fb_w * 3);
		row += pitch;
	}
	semihost_close(fd);
	LOG_INF("present: wrote %s", name);
}
```

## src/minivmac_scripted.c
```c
/*
 * SPDX-License-Identifier: Apache-2.0
 *
 * PiZZa Mini vMac -- scripted input source (CONFIG_MINIVMAC_SCRIPTED_INPUT).
 *
 * A synthetic mouse + keyboard producer that drives the booted Finder
 * through the same sdl2shim event-queue seam the `minivmac` shell (and a
 * future BT gamepad / HOGP client) use. Runs on its own thread; once System
 * 6 reaches the desktop it moves the cursor, clicks the System Folder icon to
 * select it, then issues Cmd-A (Select All) so the whole window inverts and
 * clicks empty desktop to deselect -- a visible proof of motion + click +
 * keyboard for the qemu sim gate.
 *
 * Absolute positions: Mini vMac's OSGLU takes event.motion.x/y as absolute
 * window coords, and the window is the native 512x342 Mac screen (the HVS
 * scales on hardware), so coords map 1:1 to the Mac screen. Several rounds
 * with generous spacing ride out qemu's dilated, capture-slowed timing.
 */

#include <zephyr/kernel.h>
#include <zephyr/logging/log.h>
#include <string.h>

#include "sdl2shim.h"

LOG_MODULE_REGISTER(minivmac_scripted, CONFIG_SDL2SHIM_LOG_LEVEL);

static void move_mouse(int x, int y)
{
	SDL_Event ev;

	memset(&ev, 0, sizeof(ev));
	ev.type = SDL_MOUSEMOTION;
	ev.motion.x = x;
	ev.motion.y = y;
	s2s_event_submit(&ev);
}

static void mouse_button(int x, int y, bool down)
{
	SDL_Event ev;

	memset(&ev, 0, sizeof(ev));
	ev.type = down ? SDL_MOUSEBUTTONDOWN : SDL_MOUSEBUTTONUP;
	ev.button.button = SDL_BUTTON_LEFT;
	ev.button.state = down ? SDL_PRESSED : SDL_RELEASED;
	ev.button.x = x;
	ev.button.y = y;
	s2s_event_submit(&ev);
}

static void click(int x, int y)
{
	mouse_button(x, y, true);
	k_msleep(120);
	mouse_button(x, y, false);
}

static void key(SDL_Scancode sc, bool down)
{
	SDL_Event ev;

	memset(&ev, 0, sizeof(ev));
	ev.type = down ? SDL_KEYDOWN : SDL_KEYUP;
	ev.key.state = down ? SDL_PRESSED : SDL_RELEASED;
	ev.key.keysym.scancode = sc;
	s2s_event_submit(&ev);
}

/* Positions on the 512x342 Mac screen, from the Phase-3 Finder capture: the
 * "System Folder" icon sits near the top-left of the open "System Startup"
 * window; empty desktop is lower-right.
 */
#define ICON_X   62
#define ICON_Y   98
#define EMPTY_X  400
#define EMPTY_Y  260

static void scripted_run(void *a, void *b, void *c)
{
	ARG_UNUSED(a);
	ARG_UNUSED(b);
	ARG_UNUSED(c);

	/* Let System 6 reach the Finder desktop before driving it. Generous:
	 * the semihost capture dilates wall-clock badly under qemu TCG.
	 */
	k_msleep(60000);

	for (int round = 0; round < 4; round++) {
		LOG_INF("scripted: round %d begins", round);

		move_mouse(256, 171);       /* cursor to centre */
		k_msleep(2500);

		move_mouse(ICON_X, ICON_Y); /* over the System Folder icon */
		k_msleep(1500);

		click(ICON_X, ICON_Y);      /* select it: the icon inverts */
		k_msleep(3000);

		key(SDL_SCANCODE_LGUI, true);   /* Cmd-A: Select All */
		k_msleep(100);
		key(SDL_SCANCODE_A, true);
		k_msleep(150);
		key(SDL_SCANCODE_A, false);
		k_msleep(100);
		key(SDL_SCANCODE_LGUI, false);
		k_msleep(3000);

		click(EMPTY_X, EMPTY_Y);    /* empty desktop: deselect */
		k_msleep(3000);
	}

	LOG_INF("scripted: timeline complete");
}

static K_THREAD_STACK_DEFINE(scripted_stack, 2048);
static struct k_thread scripted_thread;

void s2s_scripted_input_start(void)
{
	k_thread_create(&scripted_thread, scripted_stack,
			K_THREAD_STACK_SIZEOF(scripted_stack),
			scripted_run, NULL, NULL, NULL,
			K_PRIO_PREEMPT(7), 0, K_NO_WAIT);
	k_thread_name_set(&scripted_thread, "minivmac_scripted");
}
```

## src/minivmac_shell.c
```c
/*
 * SPDX-License-Identifier: Apache-2.0
 *
 * PiZZa Mini vMac -- `minivmac` shell command set (USB CDC ACM / console).
 *
 * Injects keyboard + mouse events through the same shim_event.c producer
 * seam the scripted source and a future BT gamepad / HOGP client use. This is
 * the interactive control path on hardware -- you drive the Mac over the
 * serial line until a Bluetooth pointer lands.
 *
 *   minivmac key <name>        tap: keydown + keyup
 *   minivmac down <name>       press and HOLD (e.g. shift, cmd)
 *   minivmac up <name>         release a held key
 *   minivmac tap <name> [ms]   hold <name> for ms (default 250) then release
 *   minivmac mouse <x> <y>     move the cursor to absolute 512x342 coords
 *   minivmac moverel <dx> <dy> move the cursor by a delta
 *   minivmac click [x y]       click (down+up) at [x y] or the current spot
 *   minivmac keys              list key names
 *
 * <name>: left right up down  return|enter esc space tab backspace
 *         shift ctrl alt|option cmd|gui  a..z  0..9
 */

#include <zephyr/kernel.h>
#include <zephyr/shell/shell.h>
#include <stdlib.h>
#include <string.h>
#include <strings.h>   /* strcasecmp (picolibc keeps it here) */

#include "sdl2shim.h"

#define MAC_W 512
#define MAC_H 342

struct keyname {
	const char *name;
	SDL_Scancode sc;
};

static const struct keyname keymap[] = {
	{ "left", SDL_SCANCODE_LEFT },   { "right", SDL_SCANCODE_RIGHT },
	{ "up", SDL_SCANCODE_UP },       { "down", SDL_SCANCODE_DOWN },
	{ "return", SDL_SCANCODE_RETURN }, { "enter", SDL_SCANCODE_RETURN },
	{ "esc", SDL_SCANCODE_ESCAPE },  { "escape", SDL_SCANCODE_ESCAPE },
	{ "space", SDL_SCANCODE_SPACE }, { "tab", SDL_SCANCODE_TAB },
	{ "backspace", SDL_SCANCODE_BACKSPACE },
	{ "shift", SDL_SCANCODE_LSHIFT }, { "lshift", SDL_SCANCODE_LSHIFT },
	{ "rshift", SDL_SCANCODE_RSHIFT },
	{ "ctrl", SDL_SCANCODE_LCTRL },  { "lctrl", SDL_SCANCODE_LCTRL },
	{ "alt", SDL_SCANCODE_LALT },    { "option", SDL_SCANCODE_LALT },
	{ "cmd", SDL_SCANCODE_LGUI },    { "gui", SDL_SCANCODE_LGUI },
	{ "command", SDL_SCANCODE_LGUI },
};

static SDL_Scancode lookup(const char *name)
{
	for (size_t i = 0; i < ARRAY_SIZE(keymap); i++) {
		if (strcasecmp(name, keymap[i].name) == 0) {
			return keymap[i].sc;
		}
	}
	/* single letter a..z or digit 0..9 */
	if (name[0] && name[1] == '\0') {
		char c = name[0];

		if (c >= 'a' && c <= 'z') {
			return (SDL_Scancode)(SDL_SCANCODE_A + (c - 'a'));
		}
		if (c >= 'A' && c <= 'Z') {
			return (SDL_Scancode)(SDL_SCANCODE_A + (c - 'A'));
		}
		if (c >= '1' && c <= '9') {
			return (SDL_Scancode)(SDL_SCANCODE_1 + (c - '1'));
		}
		if (c == '0') {
			return SDL_SCANCODE_0;
		}
	}
	return SDL_SCANCODE_UNKNOWN;
}

static void submit_key(SDL_Scancode sc, bool down)
{
	SDL_Event ev;

	memset(&ev, 0, sizeof(ev));
	ev.type = down ? SDL_KEYDOWN : SDL_KEYUP;
	ev.key.state = down ? SDL_PRESSED : SDL_RELEASED;
	ev.key.keysym.scancode = sc;
	s2s_event_submit(&ev);
}

static int clampi(int v, int lo, int hi)
{
	return (v < lo) ? lo : (v > hi) ? hi : v;
}

static void submit_motion(int x, int y)
{
	SDL_Event ev;

	memset(&ev, 0, sizeof(ev));
	ev.type = SDL_MOUSEMOTION;
	ev.motion.x = clampi(x, 0, MAC_W - 1);
	ev.motion.y = clampi(y, 0, MAC_H - 1);
	s2s_event_submit(&ev);
}

static void submit_button(int x, int y, bool down)
{
	SDL_Event ev;

	memset(&ev, 0, sizeof(ev));
	ev.type = down ? SDL_MOUSEBUTTONDOWN : SDL_MOUSEBUTTONUP;
	ev.button.button = SDL_BUTTON_LEFT;
	ev.button.state = down ? SDL_PRESSED : SDL_RELEASED;
	ev.button.x = clampi(x, 0, MAC_W - 1);
	ev.button.y = clampi(y, 0, MAC_H - 1);
	s2s_event_submit(&ev);
}

static int arg_key(const struct shell *sh, char *arg, SDL_Scancode *out)
{
	SDL_Scancode sc = lookup(arg);

	if (sc == SDL_SCANCODE_UNKNOWN) {
		shell_error(sh, "unknown key '%s' (try `minivmac keys`)", arg);
		return -EINVAL;
	}
	*out = sc;
	return 0;
}

static int cmd_key(const struct shell *sh, size_t argc, char **argv)
{
	SDL_Scancode sc;

	if (argc < 2 || arg_key(sh, argv[1], &sc)) {
		return -EINVAL;
	}
	submit_key(sc, true);
	submit_key(sc, false);
	shell_print(sh, "tapped %s", argv[1]);
	return 0;
}

static int cmd_down(const struct shell *sh, size_t argc, char **argv)
{
	SDL_Scancode sc;

	if (argc < 2 || arg_key(sh, argv[1], &sc)) {
		return -EINVAL;
	}
	submit_key(sc, true);
	shell_print(sh, "holding %s (`minivmac up %s` to release)", argv[1], argv[1]);
	return 0;
}

static int cmd_up(const struct shell *sh, size_t argc, char **argv)
{
	SDL_Scancode sc;

	if (argc < 2 || arg_key(sh, argv[1], &sc)) {
		return -EINVAL;
	}
	submit_key(sc, false);
	shell_print(sh, "released %s", argv[1]);
	return 0;
}

static int cmd_tap(const struct shell *sh, size_t argc, char **argv)
{
	SDL_Scancode sc;

	if (argc < 2 || arg_key(sh, argv[1], &sc)) {
		return -EINVAL;
	}

	int ms = (argc >= 3) ? atoi(argv[2]) : 250;

	if (ms <= 0) {
		ms = 250;
	}
	submit_key(sc, true);
	k_msleep(ms);
	submit_key(sc, false);
	shell_print(sh, "held %s for %d ms", argv[1], ms);
	return 0;
}

static int cmd_mouse(const struct shell *sh, size_t argc, char **argv)
{
	if (argc < 3) {
		return -EINVAL;
	}

	int x = atoi(argv[1]);
	int y = atoi(argv[2]);

	submit_motion(x, y);
	shell_print(sh, "mouse -> (%d, %d)", clampi(x, 0, MAC_W - 1),
		    clampi(y, 0, MAC_H - 1));
	return 0;
}

static int cmd_moverel(const struct shell *sh, size_t argc, char **argv)
{
	if (argc < 3) {
		return -EINVAL;
	}

	int x, y;

	(void)SDL_GetMouseState(&x, &y);
	x += atoi(argv[1]);
	y += atoi(argv[2]);
	submit_motion(x, y);
	shell_print(sh, "mouse -> (%d, %d)", clampi(x, 0, MAC_W - 1),
		    clampi(y, 0, MAC_H - 1));
	return 0;
}

static int cmd_click(const struct shell *sh, size_t argc, char **argv)
{
	int x, y;

	if (argc >= 3) {
		x = atoi(argv[1]);
		y = atoi(argv[2]);
	} else {
		(void)SDL_GetMouseState(&x, &y);
	}
	submit_button(x, y, true);
	k_msleep(80);
	submit_button(x, y, false);
	shell_print(sh, "clicked at (%d, %d)", clampi(x, 0, MAC_W - 1),
		    clampi(y, 0, MAC_H - 1));
	return 0;
}

static int cmd_keys(const struct shell *sh, size_t argc, char **argv)
{
	ARG_UNUSED(argc);
	ARG_UNUSED(argv);
	shell_print(sh, "left right up down  return/enter  esc  space  tab  "
			"backspace  shift  ctrl  alt/option  cmd/gui  a..z  0..9");
	shell_print(sh, "Mac: cmd = Command key (menu shortcuts), click selects, "
			"mouse/click coords are 0..511 x 0..341");
	return 0;
}

SHELL_STATIC_SUBCMD_SET_CREATE(sub_minivmac,
	SHELL_CMD_ARG(key,     NULL, "<name>  -- tap (down+up), e.g. `minivmac key return`", cmd_key, 2, 0),
	SHELL_CMD_ARG(down,    NULL, "<name>  -- press and hold", cmd_down, 2, 0),
	SHELL_CMD_ARG(up,      NULL, "<name>  -- release a held key", cmd_up, 2, 0),
	SHELL_CMD_ARG(tap,     NULL, "<name> [ms]  -- hold then release (default 250 ms)", cmd_tap, 2, 1),
	SHELL_CMD_ARG(mouse,   NULL, "<x> <y>  -- move cursor to absolute coords", cmd_mouse, 3, 0),
	SHELL_CMD_ARG(moverel, NULL, "<dx> <dy>  -- move cursor by a delta", cmd_moverel, 3, 0),
	SHELL_CMD_ARG(click,   NULL, "[x y]  -- click at coords or current spot", cmd_click, 1, 2),
	SHELL_CMD(keys,        NULL, "list key names", cmd_keys),
	SHELL_SUBCMD_SET_END
);

SHELL_CMD_REGISTER(minivmac, &sub_minivmac, "PiZZa Mini vMac input control (keyboard + mouse)", NULL);
```

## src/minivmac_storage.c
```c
/*
 * SPDX-License-Identifier: Apache-2.0
 *
 * PiZZa Mini vMac -- persistent disk backing on a FATFS volume
 * (CONFIG_MINIVMAC_DISK_FS).
 *
 * The boot disk lives as a real file (minivmac.dsk) on a mounted FATFS
 * volume: the microSD card on rpi_zero_2w (the BCM SDHost driver +
 * zephyr,sdmmc-disk "SD"), or a RAM-backed FAT disk on qemu for the sim
 * gate. Guest writes therefore survive a reboot. On first run the file is
 * seeded from the embedded floppy (minivmac_pack.S). minivmac_assets.c routes
 * the disk fd here when the mount succeeds and falls back to the RAM overlay
 * when it does not, so nothing regresses if there is no card.
 *
 * The mount NEVER formats the SD card: CONFIG_FS_FATFS_MOUNT_MKFS (which
 * auto-formats a blank volume) is enabled only on the qemu RAM disk, so a
 * mount failure on hardware falls back to RAM rather than wiping the card.
 */

#include <zephyr/kernel.h>
#include <zephyr/fs/fs.h>
#include <zephyr/logging/log.h>
#include <ff.h>
#include <errno.h>
#include <stdint.h>
#include <string.h>

#include "minivmac_storage.h"

#ifdef CONFIG_MINIVMAC_DISK_SELFTEST
static void disk_selftest(void);
#endif

LOG_MODULE_REGISTER(minivmac_storage, CONFIG_SDL2SHIM_LOG_LEVEL);

extern const uint8_t minivmac_disk_start[];
extern const uint8_t minivmac_disk_end[];

#define DISK_FILE  CONFIG_MINIVMAC_FS_MOUNT "/minivmac.dsk"

static FATFS fat_fs;
static struct fs_mount_t mp = {
	.type = FS_FATFS,
	.fs_data = &fat_fs,
	.mnt_point = CONFIG_MINIVMAC_FS_MOUNT,
};

static struct fs_file_t disk_file;
static bool ready;
static size_t disk_len;

static size_t seed_size(void)
{
	return (size_t)(minivmac_disk_end - minivmac_disk_start);
}

/* First run on a fresh volume: materialize minivmac.dsk from the embedded
 * floppy. Existing files (a card the user already provisioned, or a prior
 * boot) are left untouched so their writes persist.
 */
static int seed_if_absent(void)
{
	struct fs_dirent ent;

	if (fs_stat(DISK_FILE, &ent) == 0) {
		return 0;
	}

	struct fs_file_t f;

	fs_file_t_init(&f);

	int rc = fs_open(&f, DISK_FILE, FS_O_CREATE | FS_O_WRITE);

	if (rc != 0) {
		LOG_ERR("seed: fs_open(%s) = %d", DISK_FILE, rc);
		return rc;
	}

	ssize_t w = fs_write(&f, minivmac_disk_start, seed_size());

	fs_close(&f);
	if (w < 0 || (size_t)w != seed_size()) {
		LOG_ERR("seed: fs_write = %d (want %zu)", (int)w, seed_size());
		return -EIO;
	}
	LOG_INF("seeded %s from embedded floppy (%zu bytes)", DISK_FILE, seed_size());
	return 0;
}

int minivmac_storage_disk_init(void)
{
	if (ready) {
		return 0;
	}

	int rc = fs_mount(&mp);

	if (rc != 0) {
		LOG_WRN("fs_mount(%s) = %d; using the RAM disk overlay instead",
			mp.mnt_point, rc);
		return rc;
	}

#ifdef CONFIG_MINIVMAC_DISK_SELFTEST
	/* Force a fresh seed each boot so the round-trip test exercises the WRITE
	 * path with the CURRENT driver -- the card may still hold data an older
	 * (buggy) driver wrote, which would otherwise read back "corrupt" no
	 * matter how good the read path is.
	 */
	fs_unlink(DISK_FILE);
#endif
	if (seed_if_absent() != 0) {
		return -EIO;
	}

	fs_file_t_init(&disk_file);
	rc = fs_open(&disk_file, DISK_FILE, FS_O_RDWR);
	if (rc != 0) {
		LOG_ERR("fs_open(%s, rw) = %d", DISK_FILE, rc);
		return rc;
	}

	struct fs_dirent ent;

	disk_len = (fs_stat(DISK_FILE, &ent) == 0) ? (size_t)ent.size : seed_size();
	ready = true;
	LOG_INF("disk-fs ready: %s (%zu bytes)", DISK_FILE, disk_len);
#ifdef CONFIG_MINIVMAC_DISK_SELFTEST
	disk_selftest();
#endif
	return 0;
}

size_t minivmac_storage_disk_size(void)
{
	return disk_len;
}

ssize_t minivmac_storage_disk_read(void *buf, size_t n, size_t pos)
{
	if (fs_seek(&disk_file, (off_t)pos, FS_SEEK_SET) != 0) {
		return -1;
	}
	return fs_read(&disk_file, buf, n);
}

ssize_t minivmac_storage_disk_write(const void *buf, size_t n, size_t pos)
{
	if (fs_seek(&disk_file, (off_t)pos, FS_SEEK_SET) != 0) {
		return -1;
	}
	return fs_write(&disk_file, buf, n);
}

#ifdef CONFIG_MINIVMAC_DISK_SELFTEST
/* Read the whole disk back off the volume and diff it against the embedded
 * seed. On the SD card this confirms whether the SDHost PIO data path
 * round-trips faithfully (the disk-? symptom vs the RAM overlay that boots).
 */
static void disk_selftest(void)
{
	static uint8_t buf[512] __aligned(64);
	size_t sectors = seed_size() / 512;
	size_t bad = 0;
	size_t reported = 0;

	LOG_INF("selftest: reading %zu sectors back from %s ...", sectors, DISK_FILE);

	for (size_t s = 0; s < sectors; s++) {
		size_t off = s * 512;
		ssize_t r = minivmac_storage_disk_read(buf, 512, off);

		if (r != 512) {
			LOG_ERR("selftest: read @sector %zu (off %zu) = %d, aborting",
				s, off, (int)r);
			return;
		}
		if (memcmp(buf, minivmac_disk_start + off, 512) != 0) {
			bad++;
			if (reported < 4) {
				for (int k = 0; k < 512; k++) {
					if (buf[k] != minivmac_disk_start[off + k]) {
						LOG_ERR("selftest: sector %zu byte %d differs: "
							"sd=0x%02x seed=0x%02x", s, k, buf[k],
							minivmac_disk_start[off + k]);
						break;
					}
				}
				reported++;
			}
		}
	}

	if (bad == 0) {
		LOG_INF("selftest: SD round-trip OK -- all %zu sectors match the seed",
			sectors);
	} else {
		LOG_ERR("selftest: SD DATA CORRUPT -- %zu / %zu sectors differ from the seed",
			bad, sectors);
	}
}
#endif
```

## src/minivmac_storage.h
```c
/* SPDX-License-Identifier: Apache-2.0 */
#ifndef MINIVMAC_STORAGE_H
#define MINIVMAC_STORAGE_H

#include <stddef.h>
#include <sys/types.h>

/* Persistent disk backing on a mounted FATFS volume (CONFIG_MINIVMAC_DISK_FS).
 * minivmac_assets.c calls these when routing the disk fd; on failure it falls
 * back to the RAM overlay. pos-explicit (pread/pwrite style) so the fd layer
 * keeps its own position like the ROM / RAM paths.
 */

int minivmac_storage_disk_init(void);   /* 0 = FS-backed disk mounted + open */
size_t minivmac_storage_disk_size(void);
ssize_t minivmac_storage_disk_read(void *buf, size_t n, size_t pos);
ssize_t minivmac_storage_disk_write(const void *buf, size_t n, size_t pos);

#endif /* MINIVMAC_STORAGE_H */
```
